# MKW36Z4 register map
Vendor: NXP Semiconductors; Series: Kinetis_W; File version: 1.6
CPU: CM0PLUS r0p0, little endian, no MPU, no FPU, VTOR, 2 interrupt priority bits
Registers are 16-bit, read-write, no defined reset value unless marked. A register's access mark holds for its fields unless they carry their own. Offsets are from the block's base; [hi:lo] are bit positions; {n}, {i} and the like mark numbered series.

## XCVR_TX_DIG
Base 0x4005C200
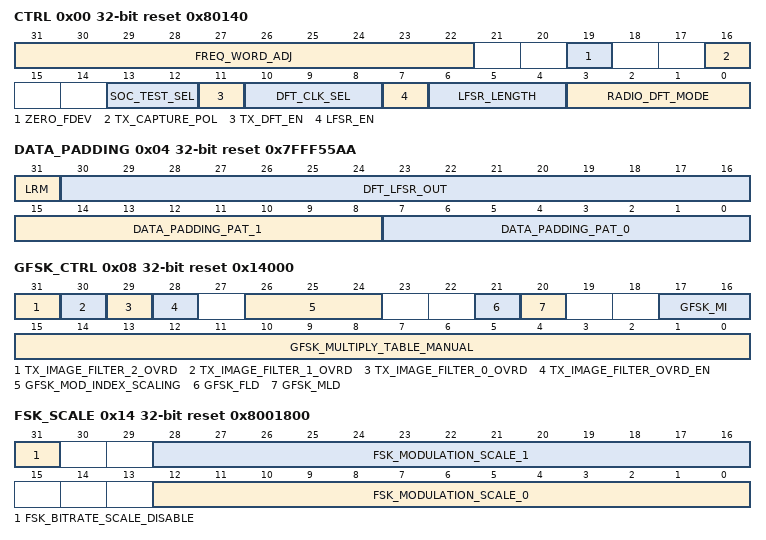
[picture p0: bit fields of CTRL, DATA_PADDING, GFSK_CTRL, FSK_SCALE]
0x00 CTRL 32-bit reset 0x80140 — TX Digital Control
  [31:22] FREQ_WORD_ADJ — Frequency Word Adjustment
  [19] ZERO_FDEV — On-Air at Zero FDev
  [16] TX_CAPTURE_POL — Polarity of the Input Data for the Transmitter
  [13:12] SOC_TEST_SEL — Radio Clock Selector for SoC RF Clock Tests
    0=No Clock Selected; 1=PLL Sigma Delta Clock, divided by 2; 2=Auxiliary PLL Clock, divided by 2; 3=RF Ref Osc clock, divided by 2
  [11] TX_DFT_EN — DFT Modulation Enable
  [10:8] DFT_CLK_SEL — DFT Clock Selection
    0=62.5 kHz; 1=125 kHz; 2=250 kHz; 3=500 kHz; 4=1 MHz; 5=2 MHz; 6=4 MHz; 7=RF OSC Clock
  [7] LFSR_EN — LFSR Enable
  [6:4] LFSR_LENGTH
    0=LFSR 9, tap mask 100010000; 1=LFSR 10, tap mask 1001000000; 2=LFSR 11, tap mask 11101000000; 3=LFSR 13, tap mask 1101100000000; 4=LFSR 15, tap mask 111010000000000; 5=LFSR 17, tap mask 11110000000000000
  [3:0] RADIO_DFT_MODE — Radio DFT Modes
    0=Normal Radio Operation, DFT not engaged; 1=Carrier Frequency Only; 2=Pattern Register GFSK; 3=LFSR GFSK; 4=Pattern Register FSK; 5=LFSR FSK; 6=Pattern Register O-QPSK; 7=LFSR O-QPSK; 8=LFSR 802.15.4 Symbols; 9=PLL Modulation from RAM; 10=PLL Coarse Tune BIST; 11=PLL Frequency Synthesizer BIST; 12=High Port DAC BIST; 13=VCO Frequency Meter
0x04 DATA_PADDING 32-bit reset 0x7FFF55AA — TX Data Padding
  [31] LRM — LFSR Reset Mask
  [30:16] DFT_LFSR_OUT ro — LFSR Output
  [15:8] DATA_PADDING_PAT_1 — Data Padding Pattern 1
  [7:0] DATA_PADDING_PAT_0 — Data Padding Pattern 0
0x08 GFSK_CTRL 32-bit reset 0x14000 — TX GFSK Modulator Control
  [31] TX_IMAGE_FILTER_2_OVRD — TX Image Filter 2 Override Control
  [30] TX_IMAGE_FILTER_1_OVRD — TX Image Filter 1 Override Control
  [29] TX_IMAGE_FILTER_0_OVRD — TX Image Filter 0 Override Control
  [28] TX_IMAGE_FILTER_OVRD_EN — TX Image Filter Override Enable
  [26:24] GFSK_MOD_INDEX_SCALING — GFSK Modulation Index Scaling Factor
    0=1; 1=1 + 1/32; 2=1 + 1/16; 3=1 + 1/8; 4=1 - 1/32; 5=1 - 1/16; 6=1 - 1/8
  [21] GFSK_FLD — Disable GFSK Filter Lookup Table
  [20] GFSK_MLD — Disable GFSK Multiply Lookup Table
  [17:16] GFSK_MI — GFSK Modulation Index
    0=0.32; 1=0.50; 2=0.70; 3=1.00
  [15:0] GFSK_MULTIPLY_TABLE_MANUAL — Manual GFSK Multiply Lookup Table Value
0x0C GFSK_COEFF2 32-bit reset 0xC0630401 — TX GFSK Filter Coefficients 2
  [31:0] GFSK_FILTER_COEFF_MANUAL2 — GFSK Manual Filter Coefficients[63:32]
0x10 GFSK_COEFF1 32-bit reset 0xBB29960D — TX GFSK Filter Coefficients 1
  [31:0] GFSK_FILTER_COEFF_MANUAL1 — GFSK Manual Filter Coefficient [31:0]
0x14 FSK_SCALE 32-bit reset 0x8001800 — TX FSK Modulation Levels
  [31] FSK_BITRATE_SCALE_DISABLE — FSK Bitrate Scaling Disable
  [28:16] FSK_MODULATION_SCALE_1 — FSK Modulation Scale for a data 1
  [12:0] FSK_MODULATION_SCALE_0 — FSK Modulation Scale for a data 0
0x18 DFT_PATTERN 32-bit reset 0x0 — TX DFT Modulation Pattern
  [31:0] DFT_MOD_PATTERN — DFT Modulation Pattern

## XCVR_PHY
Base 0x4005C400
0x00 PRE_REF0 32-bit reset 0xFDDDEB39 — PREAMBLE REFERENCE WAVEFORM 0
  [31:0] FSK_PREAMBLE_REF0 — Base preamble reference waveform containing sixteen 5-bit phase values represented in 2's complement notation using 1 sign bit and 4 fractional bits
0x04 PRE_REF1 32-bit reset 0xBEFBFFFF — PREAMBLE REFERENCE WAVEFORM 1
  [31:0] FSK_PREAMBLE_REF1 — Refer to FSK_PREAMBLE_REF0.
0x08 PRE_REF2 32-bit reset 0xCE75 — PREAMBLE REFERENCE WAVEFORM 2
  [15:0] FSK_PREAMBLE_REF2 — Refer to FSK_PREAMBLE_REF0.
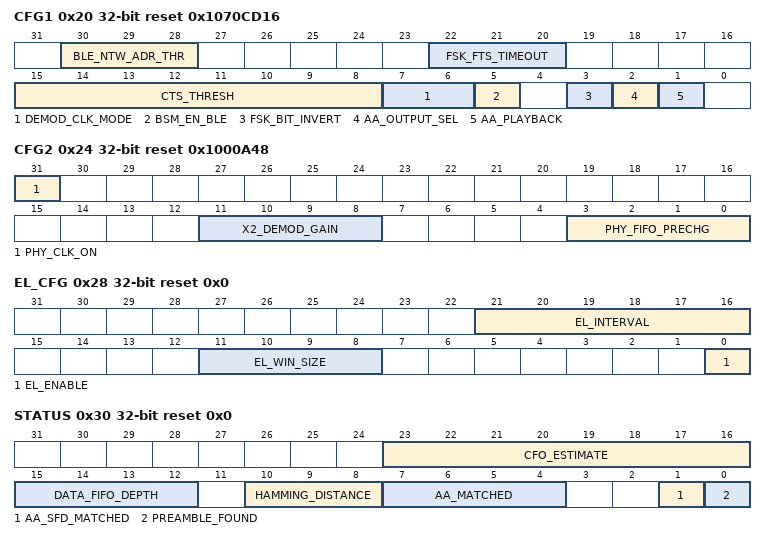
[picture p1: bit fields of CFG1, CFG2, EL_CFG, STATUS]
0x20 CFG1 32-bit reset 0x1070CD16 — PHY CONFIGURATION REGISTER 1
  [30:28] BLE_NTW_ADR_THR — BLE Network Address Match Bit Error Threshold
  [22:20] FSK_FTS_TIMEOUT
    {v}={v+4} symbols (v=0..7)
  [15:8] CTS_THRESH — CTS Correlation Threshold
  [7:6] DEMOD_CLK_MODE — Demodulator Clock Mode
    0=Normal; 1=Demodulate all samples
  [5] BSM_EN_BLE — BLE Bit Streaming Mode Enable bit
    0=BSM for BLE disabled; 1=BSM for BLE enabled
  [3] FSK_BIT_INVERT
  [2] AA_OUTPUT_SEL — Access Address Output Select
    0=demodulated; 1=matched
  [1] AA_PLAYBACK — Access Address Playback
0x24 CFG2 32-bit reset 0x1000A48 — PHY CONFIGURATION REGISTER 2
  [31] PHY_CLK_ON — Force PHY Clock On (testmode)
    0=PHY clock is enabled by TSM output: rx_phy_en; 1=PHY clock is forced on at all times
  [11:8] X2_DEMOD_GAIN
  [3:0] PHY_FIFO_PRECHG — PHY FIFO Precharge Level
0x28 EL_CFG 32-bit reset 0x0 — PHY EARLY/LATE CONFIGURATION REGISTER
  [21:16] EL_INTERVAL
  [11:8] EL_WIN_SIZE
  [0] EL_ENABLE
    0=Disable Early/Late; 1=Enable Early/Late
0x2C NTW_ADR_BSM 32-bit reset 0x0 — PHY NETWORK ADDRESS FOR BSM
0x30 STATUS 32-bit ro reset 0x0 — PHY STATUS REGISTER
  [23:16] CFO_ESTIMATE — Carrier Frequency Offset Estimate
  [15:12] DATA_FIFO_DEPTH
  [10:8] HAMMING_DISTANCE
  [7:4] AA_MATCHED — Access Address Matched
    0=No Network Address has matched; 1=Network Address 0 has matched; 2=Network Address 1 has matched; 4=Network Address 2 has matched; 8=Network Address 3 has matched
  [1] AA_SFD_MATCHED — Access Address or SFD Found
  [0] PREAMBLE_FOUND
